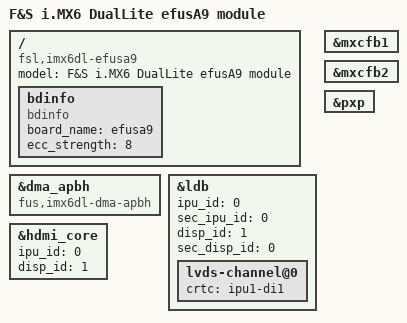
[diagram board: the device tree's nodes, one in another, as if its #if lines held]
/*
 * Copyright (C) 2016 F&S Elektronik Systeme GmbH
 *
 * This program is free software; you can redistribute it and/or modify
 * it under the terms of the GNU General Public License version 2 as
 * published by the Free Software Foundation.
 */

/dts-v1/;
// #define CONFIG_EFUSA9_REV110 // old board revision
#define CONFIG_EFUSA9_REV121

/* The following display config will be converted to Kconfig in the future */
/* Define this if you have at least one display (D0) */
#define CONFIG_EFUSA9_D0

#ifdef CONFIG_EFUSA9_D0
/* Activate exactly one entry for the type of display D0 */
#define CONFIG_EFUSA9_D0_LCD				// LCD
//#define CONFIG_EFUSA9_D0_LVDS				// LVDS
//#define CONFIG_EFUSA9_D0_HDMI				// HDMI

/*
 * Define a mode_str entry for display D0 (depends on display type above)
 * See the following files for possible values:
 *   LVDS: drivers/video/mxc/ldb.c
 *   LCD:  drivers/video/mxc/mxc_lcdif.c
 *   HDMI: drivers/video/mxc/mxc_hdmi.c (actually fetched from panel via EDID)
 */
 #ifdef CONFIG_EFUSA9_D0_LCD
 	#define CONFIG_EFUSA9_D0_MODE_STR "LCD-ET070080"	// LCD
 #elif defined(CONFIG_EFUSA9_D0_LVDS)
 	#define CONFIG_EFUSA9_D0_MODE_STR "LDB-WVGA"		// LVDS
 #elif defined(CONFIG_EFUSA9_D0_HDMI)
 	#define CONFIG_EFUSA9_D0_MODE_STR "1920x1080M@60"	// HDMI
 #endif
#endif // CONFIG_EFUSA9_D0
/* Define this if you have a second display (D1) */
#define CONFIG_EFUSA9_D1

#ifdef CONFIG_EFUSA9_D1
/* Activate exactly one entry for the type of display D1 */
#define CONFIG_EFUSA9_D1_LVDS				// LVDS
//#define CONFIG_EFUSA9_D1_HDMI				// HDMI
//#define CONFIG_EFUSA9_D1_LCD				// LCD

/* Define a mode_str entry for display D1 (see comment for D0 above) */
#ifdef CONFIG_EFUSA9_D1_LVDS
	#define CONFIG_EFUSA9_D1_MODE_STR "LDB-WVGA"		// LVDS
#elif defined(CONFIG_EFUSA9_D1_HDMI)
	#define CONFIG_EFUSA9_D1_MODE_STR "1920x1080M@60"	// HDMI
#elif	defined(CONFIG_EFUSA9_D1_LCD)
	#define CONFIG_EFUSA9_D1_MODE_STR "LCD-ET070080"	// LCD
#endif

#endif // CONFIG_EFUSA9_D1


/* Do some settings to make configurations easier */
#if defined(CONFIG_EFUSA9_D0_LVDS) || defined(CONFIG_EFUSA9_D1_LVDS)
#define CONFIG_EFUSA9_LVDS
#if defined(CONFIG_EFUSA9_D0_LVDS) && defined(CONFIG_EFUSA9_D1_LVDS)
#define CONFIG_EFUSA9_LVDS_MODE "sep1"
#else
//#define CONFIG_EFUSA9_LVDS_MODE "sin0"	// Single-channel on LVDS0
#define CONFIG_EFUSA9_LVDS_MODE "sin1"		// Single-channel on LVDS1
//#define CONFIG_EFUSA9_LVDS_MODE "dul1"	// Clone mode
//#define CONFIG_EFUSA9_LVDS_MODE "spl1"	// Dual-channel LVDS
#endif
#endif

#if defined(CONFIG_EFUSA9_D0_LCD) || defined(CONFIG_EFUSA9_D1_LCD)
#define CONFIG_EFUSA9_LCD
#endif

#define CONFIG_EFUSA9_HDMI

#ifdef CONFIG_EFUSA9_HDMI
#define CONFIG_EFUSA9_HDMI_AUDIO
#define CONFIG_EFUSA9_HDMI_CEC
#endif

/* Please select only one of the following touch devices. Make sure that the
   corresponding touchscreen driver is activated in the kernel */
//#define CONFIG_EFUSA9_4WTOUCH_SX8655_ONBOARD
#define CONFIG_EFUSA9_4WTOUCH_SX8655_RGBADAPTER
//#define CONFIG_EFUSA9_CAPTOUCH_MXT224
//#define CONFIG_EFUSA9_CAPTOUCH_FT5x06

#define CONFIG_EFUSA9_NAND
#define CONFIG_EFUSA9_SGTL5000_AUDIO

#define CONFIG_EFUSA9_CAMERA_INTERFACE
//#define CONFIG_EFUSA9_PARALLEL_INTERFACE
#define CONFIG_EFUSA9_SERIAL_INTERFACE

#define CONFIG_EFUSA9_SD_A
#define CONFIG_EFUSA9_SD_B
//#define CONFIG_EFUSA9_EMMC

#define CONFIG_EFUSA9_I2C_A
#define CONFIG_EFUSA9_I2C_B
#define CONFIG_EFUSA9_I2C_C

#define CONFIG_EFUSA9_SPI_A
#define CONFIG_EFUSA9_SPI_B

#define CONFIG_EFUSA9_UART_A
#define CONFIG_EFUSA9_UART_B
#define CONFIG_EFUSA9_UART_C
#define CONFIG_EFUSA9_UART_D

#include "imx6dl.dtsi"
#include "fsimx6qdl-efusa9.dtsi"

/ {
	model = "F&S i.MX6 DualLite efusA9 module";
	compatible = "fsl,imx6dl-efusa9", "fsl,imx6dl";

	/* -------------------- BOARD INFO -------------------- */
	bdinfo {
		compatible = "bdinfo";
		board_name = "efusa9";
		ecc_strength = "8";
	};
};

&dma_apbh {
	/* Switch to F&S implementation of APBH DMA driver for GPMI (NAND) */
	compatible = "fus,imx6dl-dma-apbh", "fus,imx28-dma-apbh";
};

#ifdef CONFIG_EFUSA9_LVDS
&ldb {
	ipu_id = <0>;
	sec_ipu_id = <0>;
#ifdef CONFIG_EFUSA9_LCD
	disp_id = <1>;
	sec_disp_id = <0>;
	lvds-channel@0 {
		crtc = "ipu1-di1";
		status = "okay";
	};
#else
	disp_id = <0>;
	sec_disp_id = <1>;
	lvds-channel@0 {
		crtc = "ipu1-di0";
		status = "okay";
	};
#endif
};
#endif

#ifdef CONFIG_EFUSA9_HDMI
&hdmi_core {
	ipu_id = <0>;
	disp_id = <1>;
	status = "okay";
};
#endif
#ifdef CONFIG_EFUSA9_D0
&mxcfb1 {
	status = "okay";
};
#endif
#ifdef CONFIG_EFUSA9_D1
&mxcfb2 {
	status = "okay";
};
#endif
&pxp {
	status = "okay";
};
